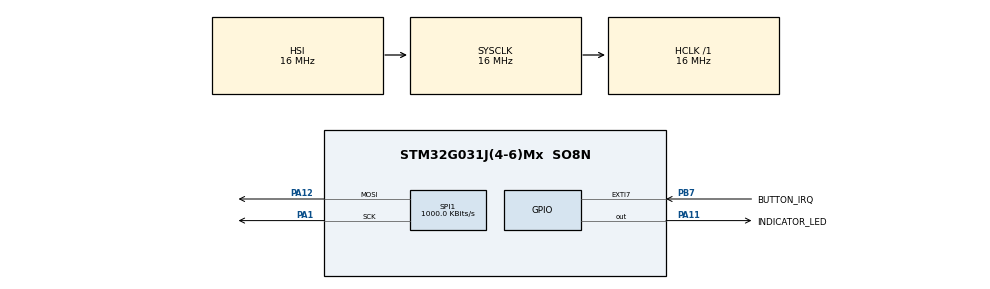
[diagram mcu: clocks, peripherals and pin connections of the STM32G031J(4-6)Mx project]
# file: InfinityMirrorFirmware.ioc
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Dma.Request0=SPI1_TX
Dma.SPI1_TX.0.Direction=DMA_MEMORY_TO_PERIPH
Dma.SPI1_TX.0.EventEnable=DISABLE
Dma.SPI1_TX.0.Instance=DMA1_Channel1
Dma.SPI1_TX.0.MemDataAlignment=DMA_MDATAALIGN_BYTE
Dma.SPI1_TX.0.MemInc=DMA_MINC_ENABLE
Dma.SPI1_TX.0.Mode=DMA_NORMAL
Dma.SPI1_TX.0.PeriphDataAlignment=DMA_PDATAALIGN_BYTE
Dma.SPI1_TX.0.PeriphInc=DMA_PINC_DISABLE
Dma.SPI1_TX.0.Polarity=HAL_DMAMUX_REQ_GEN_RISING
Dma.SPI1_TX.0.Priority=DMA_PRIORITY_HIGH
Dma.SPI1_TX.0.RequestNumber=1
Dma.SPI1_TX.0.SignalID=NONE
Dma.SPI1_TX.0.SyncEnable=DISABLE
Dma.SPI1_TX.0.SyncPolarity=HAL_DMAMUX_SYNC_NO_EVENT
Dma.SPI1_TX.0.SyncRequestNumber=1
Dma.SPI1_TX.0.SyncSignalID=NONE
Mcu.Family=STM32G0
Mcu.Name=STM32G031J(4-6)Mx
Mcu.Package=SO8N
NVIC.DMA1_Channel1_IRQn=true\:0\:0\:false\:false\:true\:false\:true
NVIC.EXTI4_15_IRQn=true\:0\:0\:false\:false\:true\:true\:true
PA1.Mode=TX_Only_Simplex_Unidirect_Master
PA1.Signal=SPI1_SCK
PA11\ [PA9].GPIO_Label=INDICATOR_LED
PA11\ [PA9].Signal=GPIO_Output
PA12\ [PA10].Mode=TX_Only_Simplex_Unidirect_Master
PA12\ [PA10].Signal=SPI1_MOSI
PA13.Mode=Serial_Wire
PA13.Signal=SYS_SWDIO
PA14-BOOT0.Mode=Serial_Wire
PA14-BOOT0.Signal=SYS_SWCLK
PB7.GPIO_Label=BUTTON_IRQ
PB7.Signal=GPXTI7
ProjectManager.HeapSize=0x200
ProjectManager.StackSize=0x400
ProjectManager.TargetToolchain=STM32CubeIDE
RCC.AHBFreq_Value=16000000
RCC.CortexFreq_Value=16000000
RCC.EXTERNAL_CLOCK_VALUE=12288000
RCC.HCLKFreq_Value=16000000
RCC.HSE_VALUE=8000000
RCC.HSI_VALUE=16000000
RCC.LSE_VALUE=32768
RCC.SYSCLKFreq_VALUE=16000000
RCC.VCOOutputFreq_Value=128000000
SPI1.BaudRatePrescaler=SPI_BAUDRATEPRESCALER_16
SPI1.CalculateBaudRate=1000.0 KBits/s
SPI1.Direction=SPI_DIRECTION_2LINES
SPI1.Mode=SPI_MODE_MASTER
SPI1.VirtualType=VM_MASTER
board=custom

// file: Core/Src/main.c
/* USER CODE BEGIN Header */
/**
  ******************************************************************************
  * @file           : main.c
  * @brief          : Main program body
  ******************************************************************************
  * @attention
  *
  * <h2><center>&copy; Copyright (c) 2020 STMicroelectronics.
  * All rights reserved.</center></h2>
  *
  * This software component is licensed by ST under BSD 3-Clause license,
  * the "License"; You may not use this file except in compliance with the
  * License. You may obtain a copy of the License at:
  *                        opensource.org/licenses/BSD-3-Clause
  *
  ******************************************************************************
  */
/* USER CODE END Header */
#include "main.h"
#include "dma.h"
#include "spi.h"
#include "gpio.h"

void SystemClock_Config(void);

int main(void)
{

  /* MCU Configuration--------------------------------------------------------*/

  /* Reset of all peripherals, Initializes the Flash interface and the Systick. */
  HAL_Init();

  /* Configure the system clock */
  SystemClock_Config();

  /* Initialize all configured peripherals */
  MX_GPIO_Init();
  MX_DMA_Init();
  MX_SPI1_Init();
  /* USER CODE BEGIN 2 */
  static const uint32_t STORAGE=FLASH_PAGE_NB-1;
  uint32_t *startStorageAddress = STORAGE*FLASH_PAGE_SIZE+FLASH_BASE;
  if(((*startStorageAddress)&0xFF)==0xFF) {
	  if(HAL_OK!=HAL_FLASH_Program(FLASH_TYPEPROGRAM_DOUBLEWORD, startStorageAddress, 0x0000000000000000)) {
  			//blink LED
	  }
  } else if (((*startStorageAddress)&0xFF)==0x00) {
	  //search for first 0xFF, then move back 8 bytes and read value
  } else {
	  //error
  }
  //HAL_FLASH_Program(TypeProgram, Address, Data)

  /* USER CODE END 2 */

  /* Infinite loop */
  while (1)
  {

  }
}

void SystemClock_Config(void)
{
  RCC_OscInitTypeDef RCC_OscInitStruct = {0};
  RCC_ClkInitTypeDef RCC_ClkInitStruct = {0};

  /** Configure the main internal regulator output voltage
  */
  HAL_PWREx_ControlVoltageScaling(PWR_REGULATOR_VOLTAGE_SCALE1);
  /** Initializes the RCC Oscillators according to the specified parameters
  * in the RCC_OscInitTypeDef structure.
  */
  RCC_OscInitStruct.OscillatorType = RCC_OSCILLATORTYPE_HSI;
  RCC_OscInitStruct.HSIState = RCC_HSI_ON;
  RCC_OscInitStruct.HSIDiv = RCC_HSI_DIV1;
  RCC_OscInitStruct.HSICalibrationValue = RCC_HSICALIBRATION_DEFAULT;
  RCC_OscInitStruct.PLL.PLLState = RCC_PLL_NONE;
  if (HAL_RCC_OscConfig(&RCC_OscInitStruct) != HAL_OK)
  {
    Error_Handler();
  }
  /** Initializes the CPU, AHB and APB buses clocks
  */
  RCC_ClkInitStruct.ClockType = RCC_CLOCKTYPE_HCLK|RCC_CLOCKTYPE_SYSCLK
                              |RCC_CLOCKTYPE_PCLK1;
  RCC_ClkInitStruct.SYSCLKSource = RCC_SYSCLKSOURCE_HSI;
  RCC_ClkInitStruct.AHBCLKDivider = RCC_SYSCLK_DIV1;
  RCC_ClkInitStruct.APB1CLKDivider = RCC_HCLK_DIV1;

  if (HAL_RCC_ClockConfig(&RCC_ClkInitStruct, FLASH_LATENCY_0) != HAL_OK)
  {
    Error_Handler();
  }
}

void Error_Handler(void)
{
}

/************************ (C) COPYRIGHT STMicroelectronics *****END OF FILE****/
